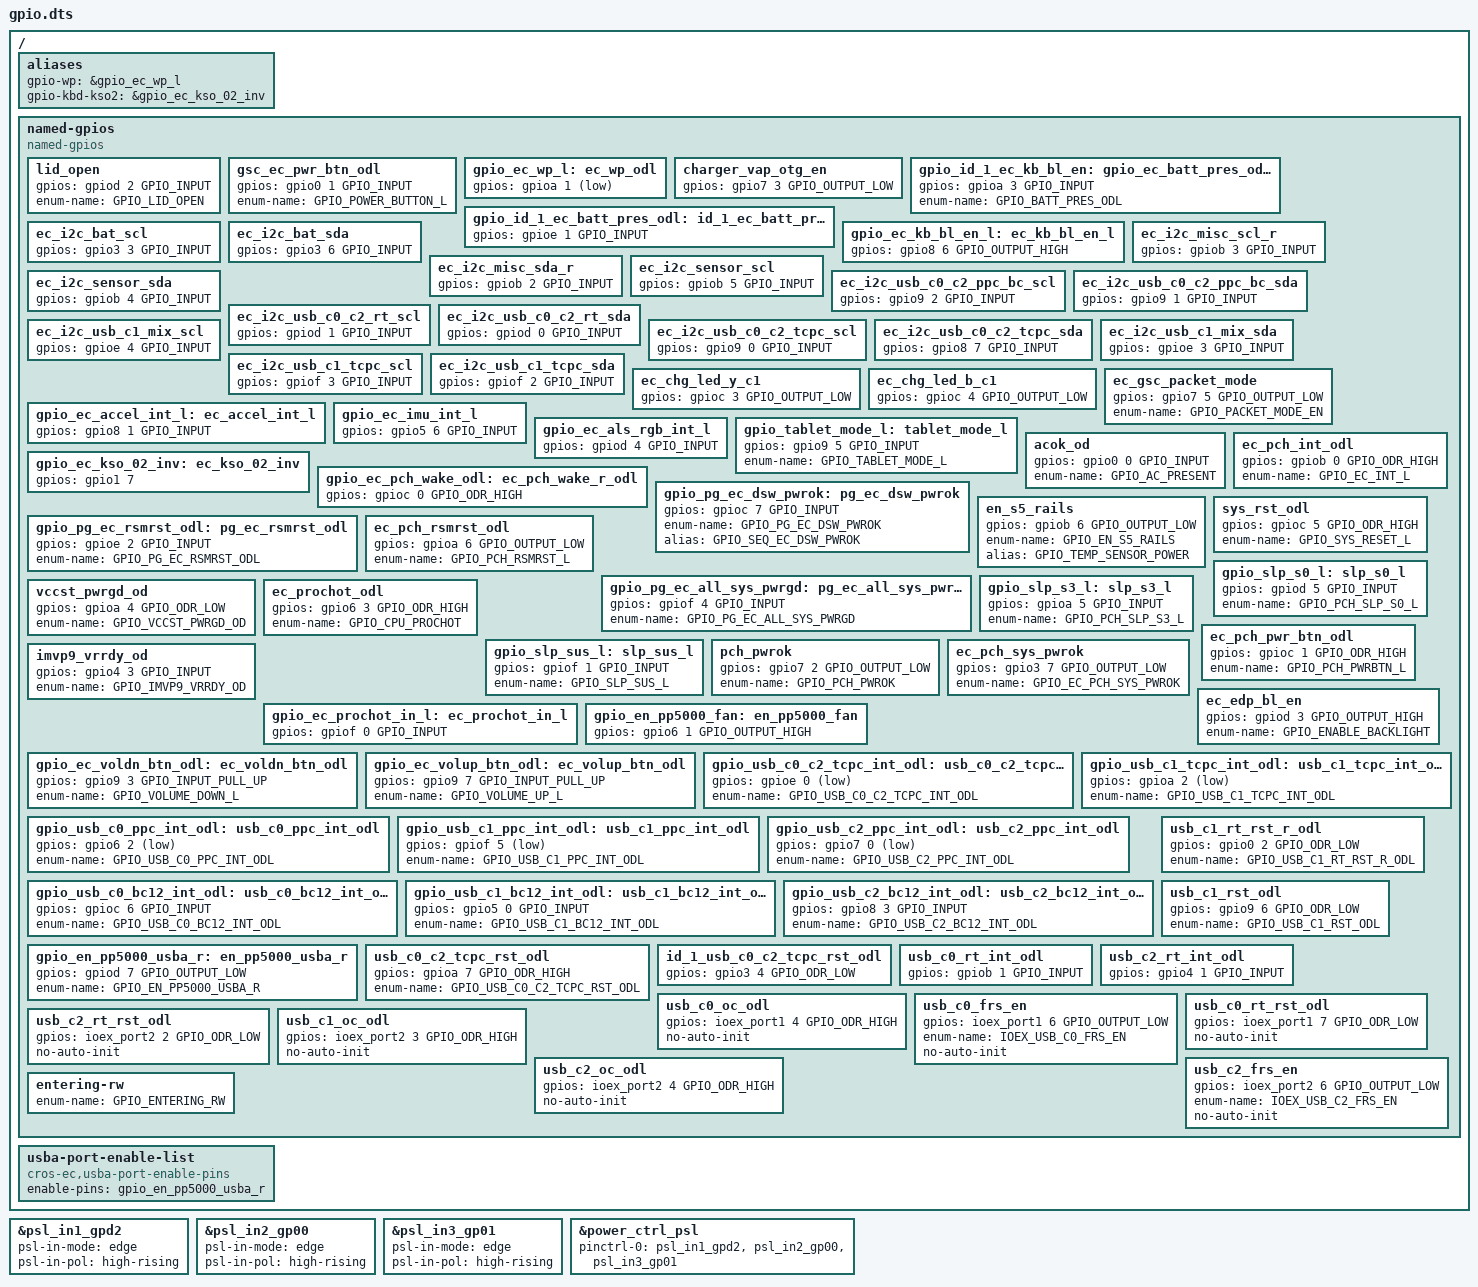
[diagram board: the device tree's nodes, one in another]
/* Copyright 2021 The ChromiumOS Authors
 * Use of this source code is governed by a BSD-style license that can be
 * found in the LICENSE file.
 */

/ {
	aliases {
		gpio-wp = &gpio_ec_wp_l;
		gpio-kbd-kso2 = &gpio_ec_kso_02_inv;
	};

	named-gpios {
		compatible = "named-gpios";

		lid_open: lid_open {
			gpios = <&gpiod 2 GPIO_INPUT>;
			enum-name = "GPIO_LID_OPEN";
		};
		gsc_ec_pwr_btn_odl: gsc_ec_pwr_btn_odl {
			gpios = <&gpio0 1 GPIO_INPUT>;
			enum-name = "GPIO_POWER_BUTTON_L";
		};
		gpio_ec_wp_l: ec_wp_odl {
			gpios = <&gpioa 1 (GPIO_INPUT | GPIO_ACTIVE_LOW)>;
		};
		charger_vap_otg_en {
			gpios = <&gpio7 3 GPIO_OUTPUT_LOW>;
		};

		/*
		 * Board ID 1 repurposes the gpio_ec_batt_pres_odl pin as
		 * an output signal.  The board code switches the pin
		 * pin configuration to an output when board ID 1 is detected.
		 */
		gpio_id_1_ec_kb_bl_en: gpio_ec_batt_pres_odl: ec_batt_pres_odl {
			gpios = <&gpioa 3 GPIO_INPUT>;
			enum-name = "GPIO_BATT_PRES_ODL";
		};
		gpio_id_1_ec_batt_pres_odl: id_1_ec_batt_pres_odl {
			gpios = <&gpioe 1 GPIO_INPUT>;
		};
		ec_i2c_bat_scl {
			gpios = <&gpio3 3 GPIO_INPUT>;
		};
		ec_i2c_bat_sda {
			gpios = <&gpio3 6 GPIO_INPUT>;
		};
		gpio_ec_kb_bl_en_l: ec_kb_bl_en_l {
			gpios = <&gpio8 6 GPIO_OUTPUT_HIGH>;
		};
		ec_i2c_misc_scl_r {
			gpios = <&gpiob 3 GPIO_INPUT>;
		};
		ec_i2c_misc_sda_r {
			gpios = <&gpiob 2 GPIO_INPUT>;
		};
		ec_i2c_sensor_scl {
			gpios = <&gpiob 5 GPIO_INPUT>;
		};
		ec_i2c_sensor_sda {
			gpios = <&gpiob 4 GPIO_INPUT>;
		};
		ec_i2c_usb_c0_c2_ppc_bc_scl {
			gpios = <&gpio9 2 GPIO_INPUT>;
		};
		ec_i2c_usb_c0_c2_ppc_bc_sda {
			gpios = <&gpio9 1 GPIO_INPUT>;
		};
		ec_i2c_usb_c0_c2_rt_scl {
			gpios = <&gpiod 1 GPIO_INPUT>;
		};
		ec_i2c_usb_c0_c2_rt_sda {
			gpios = <&gpiod 0 GPIO_INPUT>;
		};
		ec_i2c_usb_c0_c2_tcpc_scl {
			gpios = <&gpio9 0 GPIO_INPUT>;
		};
		ec_i2c_usb_c0_c2_tcpc_sda {
			gpios = <&gpio8 7 GPIO_INPUT>;
		};
		ec_i2c_usb_c1_mix_scl {
			gpios = <&gpioe 4 GPIO_INPUT>;
		};
		ec_i2c_usb_c1_mix_sda {
			gpios = <&gpioe 3 GPIO_INPUT>;
		};
		ec_i2c_usb_c1_tcpc_scl {
			gpios = <&gpiof 3 GPIO_INPUT>;
		};
		ec_i2c_usb_c1_tcpc_sda {
			gpios = <&gpiof 2 GPIO_INPUT>;
		};
		ec_chg_led_y_c1 {
			gpios = <&gpioc 3 GPIO_OUTPUT_LOW>;
		};
		ec_chg_led_b_c1 {
			gpios = <&gpioc 4 GPIO_OUTPUT_LOW>;
		};
		ec_gsc_packet_mode {
			gpios = <&gpio7 5 GPIO_OUTPUT_LOW>;
			enum-name = "GPIO_PACKET_MODE_EN";
		};
		gpio_ec_accel_int_l: ec_accel_int_l {
			gpios = <&gpio8 1 GPIO_INPUT>;
		};
		gpio_ec_imu_int_l: gpio_ec_imu_int_l {
			gpios = <&gpio5 6 GPIO_INPUT>;
		};
		gpio_ec_als_rgb_int_l: gpio_ec_als_rgb_int_l {
			gpios = <&gpiod 4 GPIO_INPUT>;
		};
		gpio_tablet_mode_l: tablet_mode_l {
			gpios = <&gpio9 5 GPIO_INPUT>;
			enum-name = "GPIO_TABLET_MODE_L";
		};
		acok_od: acok_od {
			gpios = <&gpio0 0 GPIO_INPUT>;
			enum-name = "GPIO_AC_PRESENT";
		};
		gpio_ec_kso_02_inv: ec_kso_02_inv {
			gpios = <&gpio1 7 (GPIO_OUTPUT | GPIO_ACTIVE_HIGH)>;
		};
		gpio_ec_pch_wake_odl: ec_pch_wake_r_odl {
			gpios = <&gpioc 0 GPIO_ODR_HIGH>;
		};
		ec_pch_int_odl {
			gpios = <&gpiob 0 GPIO_ODR_HIGH>;
			enum-name = "GPIO_EC_INT_L";
		};
		gpio_pg_ec_dsw_pwrok: pg_ec_dsw_pwrok {
			gpios = <&gpioc 7 GPIO_INPUT>;
			enum-name = "GPIO_PG_EC_DSW_PWROK";
			alias = "GPIO_SEQ_EC_DSW_PWROK";
		};
		en_s5_rails {
			gpios = <&gpiob 6 GPIO_OUTPUT_LOW>;
			enum-name = "GPIO_EN_S5_RAILS";
			alias = "GPIO_TEMP_SENSOR_POWER";
		};
		sys_rst_odl {
			gpios = <&gpioc 5 GPIO_ODR_HIGH>;
			enum-name = "GPIO_SYS_RESET_L";
		};
		gpio_pg_ec_rsmrst_odl: pg_ec_rsmrst_odl {
			gpios = <&gpioe 2 GPIO_INPUT>;
			enum-name = "GPIO_PG_EC_RSMRST_ODL";
		};
		ec_pch_rsmrst_odl {
			gpios = <&gpioa 6 GPIO_OUTPUT_LOW>;
			enum-name = "GPIO_PCH_RSMRST_L";
		};
		gpio_pg_ec_all_sys_pwrgd: pg_ec_all_sys_pwrgd {
			gpios = <&gpiof 4 GPIO_INPUT>;
			enum-name = "GPIO_PG_EC_ALL_SYS_PWRGD";
		};
		gpio_slp_s0_l: slp_s0_l {
			gpios = <&gpiod 5 GPIO_INPUT>;
			enum-name = "GPIO_PCH_SLP_S0_L";
		};
		gpio_slp_s3_l: slp_s3_l {
			gpios = <&gpioa 5 GPIO_INPUT>;
			enum-name = "GPIO_PCH_SLP_S3_L";
		};
		vccst_pwrgd_od {
			gpios = <&gpioa 4 GPIO_ODR_LOW>;
			enum-name = "GPIO_VCCST_PWRGD_OD";
		};
		ec_prochot_odl {
			gpios = <&gpio6 3 GPIO_ODR_HIGH>;
			enum-name = "GPIO_CPU_PROCHOT";
		};
		ec_pch_pwr_btn_odl {
			gpios = <&gpioc 1 GPIO_ODR_HIGH>;
			enum-name = "GPIO_PCH_PWRBTN_L";
		};
		gpio_slp_sus_l: slp_sus_l {
			gpios = <&gpiof 1 GPIO_INPUT>;
			enum-name = "GPIO_SLP_SUS_L";
		};
		pch_pwrok {
			gpios = <&gpio7 2 GPIO_OUTPUT_LOW>;
			enum-name = "GPIO_PCH_PWROK";
		};
		ec_pch_sys_pwrok {
			gpios = <&gpio3 7 GPIO_OUTPUT_LOW>;
			enum-name = "GPIO_EC_PCH_SYS_PWROK";
		};
		imvp9_vrrdy_od {
			gpios = <&gpio4 3 GPIO_INPUT>;
			enum-name = "GPIO_IMVP9_VRRDY_OD";
		};
		ec_edp_bl_en {
			gpios = <&gpiod 3 GPIO_OUTPUT_HIGH>;
			enum-name = "GPIO_ENABLE_BACKLIGHT";
		};
		gpio_ec_prochot_in_l: ec_prochot_in_l {
			gpios = <&gpiof 0 GPIO_INPUT>;
		};
		gpio_en_pp5000_fan: en_pp5000_fan {
			gpios = <&gpio6 1 GPIO_OUTPUT_HIGH>;
		};
		gpio_ec_voldn_btn_odl: ec_voldn_btn_odl {
			gpios = <&gpio9 3 GPIO_INPUT_PULL_UP>;
			enum-name = "GPIO_VOLUME_DOWN_L";
		};
		gpio_ec_volup_btn_odl: ec_volup_btn_odl {
			gpios = <&gpio9 7 GPIO_INPUT_PULL_UP>;
			enum-name = "GPIO_VOLUME_UP_L";
		};
		gpio_usb_c0_c2_tcpc_int_odl: usb_c0_c2_tcpc_int_odl {
			gpios = <&gpioe 0 (GPIO_INPUT | GPIO_ACTIVE_LOW)>;
			enum-name = "GPIO_USB_C0_C2_TCPC_INT_ODL";
		};
		gpio_usb_c1_tcpc_int_odl: usb_c1_tcpc_int_odl {
			gpios = <&gpioa 2 (GPIO_INPUT | GPIO_ACTIVE_LOW)>;
			enum-name = "GPIO_USB_C1_TCPC_INT_ODL";
		};
		gpio_usb_c0_ppc_int_odl: usb_c0_ppc_int_odl {
			gpios = <&gpio6 2 (GPIO_INPUT | GPIO_ACTIVE_LOW)>;
			enum-name = "GPIO_USB_C0_PPC_INT_ODL";
		};
		gpio_usb_c1_ppc_int_odl: usb_c1_ppc_int_odl {
			gpios = <&gpiof 5 (GPIO_INPUT | GPIO_ACTIVE_LOW)>;
			enum-name = "GPIO_USB_C1_PPC_INT_ODL";
		};
		gpio_usb_c2_ppc_int_odl: usb_c2_ppc_int_odl {
			gpios = <&gpio7 0 (GPIO_INPUT | GPIO_ACTIVE_LOW)>;
			enum-name = "GPIO_USB_C2_PPC_INT_ODL";
		};
		gpio_usb_c0_bc12_int_odl: usb_c0_bc12_int_odl {
			gpios = <&gpioc 6 GPIO_INPUT>;
			enum-name = "GPIO_USB_C0_BC12_INT_ODL";
		};
		gpio_usb_c1_bc12_int_odl: usb_c1_bc12_int_odl {
			gpios = <&gpio5 0 GPIO_INPUT>;
			enum-name = "GPIO_USB_C1_BC12_INT_ODL";
		};
		gpio_usb_c2_bc12_int_odl: usb_c2_bc12_int_odl {
			gpios = <&gpio8 3 GPIO_INPUT>;
			enum-name = "GPIO_USB_C2_BC12_INT_ODL";
		};
		gpio_en_pp5000_usba_r: en_pp5000_usba_r {
			gpios = <&gpiod 7 GPIO_OUTPUT_LOW>;
			enum-name = "GPIO_EN_PP5000_USBA_R";
		};
		usb_c1_rt_rst_r_odl {
			gpios = <&gpio0 2 GPIO_ODR_LOW>;
			enum-name = "GPIO_USB_C1_RT_RST_R_ODL";
		};
		usb_c1_rst_odl {
			gpios = <&gpio9 6 GPIO_ODR_LOW>;
			enum-name = "GPIO_USB_C1_RST_ODL";
		};
		usb_c0_c2_tcpc_rst_odl {
			gpios = <&gpioa 7 GPIO_ODR_HIGH>;
			enum-name = "GPIO_USB_C0_C2_TCPC_RST_ODL";
		};
		id_1_usb_c0_c2_tcpc_rst_odl {
			gpios = <&gpio3 4 GPIO_ODR_LOW>;
		};
		usb_c0_rt_int_odl: usb_c0_rt_int_odl {
			gpios = <&gpiob 1 GPIO_INPUT>;
		};
		usb_c2_rt_int_odl: usb_c2_rt_int_odl {
			gpios = <&gpio4 1 GPIO_INPUT>;
		};
		usb_c0_oc_odl {
			gpios = <&ioex_port1 4 GPIO_ODR_HIGH>;
			no-auto-init;
		};
		usb_c0_frs_en: usb_c0_frs_en {
			gpios = <&ioex_port1 6 GPIO_OUTPUT_LOW>;
			enum-name = "IOEX_USB_C0_FRS_EN";
			no-auto-init;
		};
		usb_c0_rt_rst_odl: usb_c0_rt_rst_odl {
			gpios = <&ioex_port1 7 GPIO_ODR_LOW>;
			no-auto-init;
		};
		usb_c2_rt_rst_odl: usb_c2_rt_rst_odl {
			gpios = <&ioex_port2 2 GPIO_ODR_LOW>;
			no-auto-init;
		};
		usb_c1_oc_odl {
			gpios = <&ioex_port2 3 GPIO_ODR_HIGH>;
			no-auto-init;
		};
		usb_c2_oc_odl {
			gpios = <&ioex_port2 4 GPIO_ODR_HIGH>;
			no-auto-init;
		};
		usb_c2_frs_en: usb_c2_frs_en {
			gpios = <&ioex_port2 6 GPIO_OUTPUT_LOW>;
			enum-name = "IOEX_USB_C2_FRS_EN";
			no-auto-init;
		};
		/* unimplemented GPIOs */
		entering-rw {
			enum-name = "GPIO_ENTERING_RW";
		};
	};

	usba-port-enable-list {
		compatible = "cros-ec,usba-port-enable-pins";
		enable-pins = <&gpio_en_pp5000_usba_r>;
	};
};

/* Power switch logic input pads */
/* LID_OPEN_OD */
&psl_in1_gpd2 {
	psl-in-mode = "edge";
	psl-in-pol = "high-rising";
};

/* ACOK_EC_OD */
&psl_in2_gp00 {
	psl-in-mode = "edge";
	psl-in-pol = "high-rising";
};

/* GSC_EC_PWR_BTN_ODL */
&psl_in3_gp01 {
	psl-in-mode = "edge";
	psl-in-pol = "high-rising";
};

/* Power domain device controlled by PSL (Power Switch Logic) IO pads */
&power_ctrl_psl {
	status = "okay";
	pinctrl-names = "sleep";
	pinctrl-0 = <&psl_in1_gpd2 &psl_in2_gp00 &psl_in3_gp01>;
};
